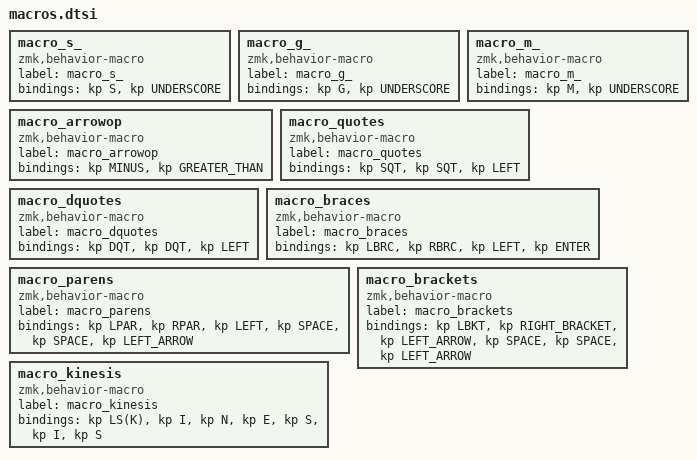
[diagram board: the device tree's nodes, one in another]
macro_s_: macro_s_{
compatible = "zmk,behavior-macro";
label = "macro_s_";
#binding-cells = <0>;
bindings = <&kp S>, <&kp UNDERSCORE>;
};
macro_g_: macro_g_{
compatible = "zmk,behavior-macro";
label = "macro_g_";
#binding-cells = <0>;
bindings = <&kp G>, <&kp UNDERSCORE>;
};
macro_arrowop: macro_arrowop{
compatible = "zmk,behavior-macro";
label = "macro_arrowop";
#binding-cells = <0>;
bindings = <&kp MINUS>, <&kp GREATER_THAN>;
};
macro_m_: macro_m_{
compatible = "zmk,behavior-macro";
label = "macro_m_";
#binding-cells = <0>;
bindings = <&kp M>, <&kp UNDERSCORE>;
};
macro_quotes: macro_quotes{
compatible = "zmk,behavior-macro";
label = "macro_quotes";
#binding-cells = <0>;
bindings = <&kp SQT>, <&kp SQT>, <&kp LEFT>;
};
macro_dquotes: macro_dquotes{
compatible = "zmk,behavior-macro";
label = "macro_dquotes";
#binding-cells = <0>;
bindings = <&kp DQT>, <&kp DQT>, <&kp LEFT>;
};
macro_braces: macro_braces{
compatible = "zmk,behavior-macro";
label = "macro_braces";
#binding-cells = <0>;
bindings = <&kp LBRC>, <&kp RBRC>, <&kp LEFT>, <&kp ENTER>;
};
macro_parens: macro_parens{
compatible = "zmk,behavior-macro";
label = "macro_parens";
#binding-cells = <0>;
bindings = <&kp LPAR>, <&kp RPAR>, <&kp LEFT>, <&kp SPACE>, <&kp SPACE>, <&kp LEFT_ARROW>;
};
macro_brackets: macro_brackets{
compatible = "zmk,behavior-macro";
label = "macro_brackets";
#binding-cells = <0>;
bindings = <&kp LBKT>, <&kp RIGHT_BRACKET>, <&kp LEFT_ARROW>, <&kp SPACE>, <&kp SPACE>, <&kp LEFT_ARROW>;
};
macro_kinesis: macro_kinesis{
compatible = "zmk,behavior-macro";
label = "macro_kinesis";
#binding-cells = <0>;
bindings = <&kp LS(K)>, <&kp I>, <&kp N>, <&kp E>, <&kp S>, <&kp I>, <&kp S>;
};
